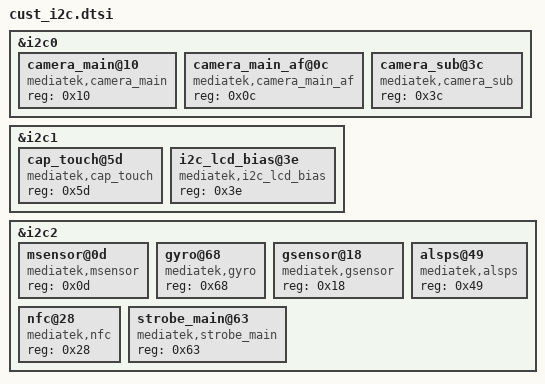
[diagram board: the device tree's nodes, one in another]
/*
 * Generated by MTK SP Drv_CodeGen Version 03.13.6  for MT6735. Copyright MediaTek Inc. (C) 2013.
 * Thu Jun  4 21:49:55 2015
 * Do Not Modify the File.
 */

/*************************
 * I2C dtsi file
*************************/

&i2c0 {
	camera_main@10 {
		compatible = "mediatek,camera_main";
		reg = <0x10>;
	};

	camera_main_af@0c {
		compatible = "mediatek,camera_main_af";
		reg = <0x0c>;
	};

	camera_sub@3c {
		compatible = "mediatek,camera_sub";
		reg = <0x3c>;
	};

};

&i2c1 {
	cap_touch@5d {
		compatible = "mediatek,cap_touch";
		reg = <0x5d>;
	};

	i2c_lcd_bias@3e {
		compatible = "mediatek,i2c_lcd_bias";
		reg = <0x3e>;
	};

};

&i2c2 {
	msensor@0d {
		compatible = "mediatek,msensor";
		reg = <0x0d>;
	};

	gyro@68 {
		compatible = "mediatek,gyro";
		reg = <0x68>;
	};

	gsensor@18 {
		compatible = "mediatek,gsensor";
		reg = <0x18>;
	};

	alsps@49 {
		compatible = "mediatek,alsps";
		reg = <0x49>;
	};

	nfc@28 {
		compatible = "mediatek,nfc";
		reg = <0x28>;
	};

	strobe_main@63 {
		compatible = "mediatek,strobe_main";
		reg = <0x63>;
	};
};
